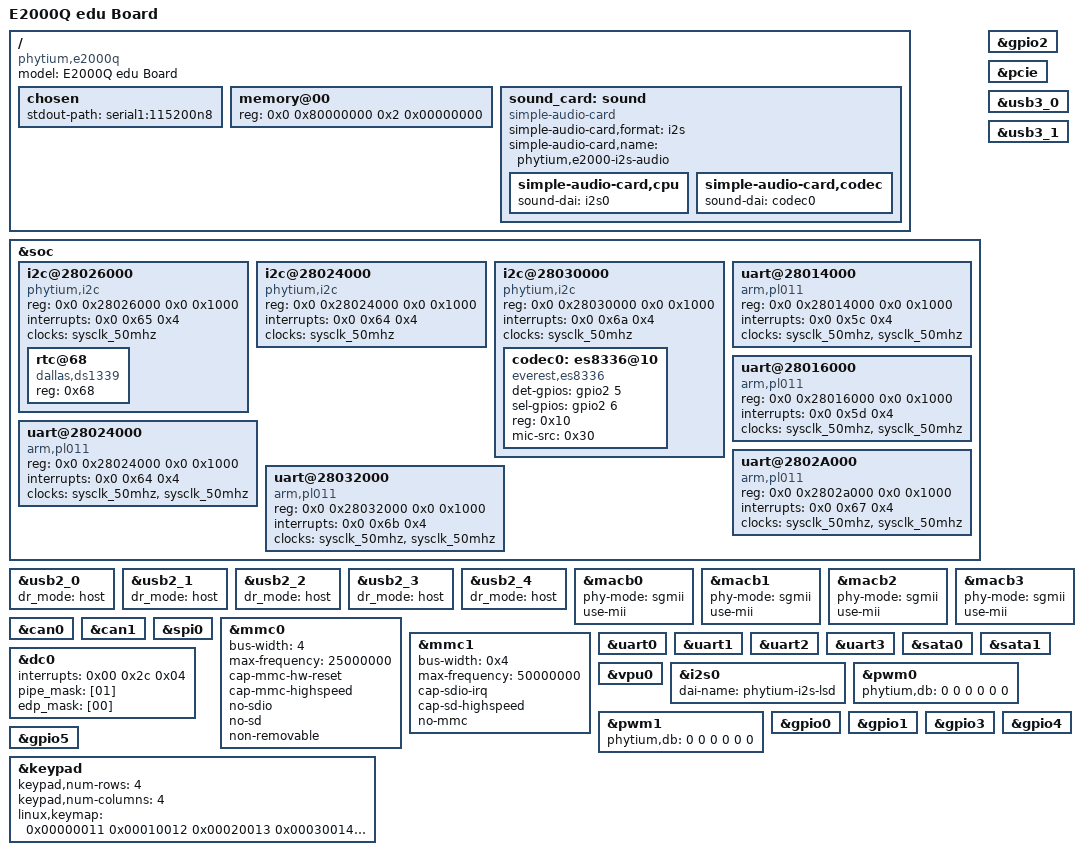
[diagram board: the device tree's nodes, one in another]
// SPDX-License-Identifier: GPL-2.0
/*
 * DTS file for Phytium E2000Q edu board
 *
 * Copyright (C) 2022, Phytium Technology Co., Ltd.
 *
 * Hongmin Qi <qihongmin@phytium.com.cn>
 */

/dts-v1/;
/memreserve/ 0x80000000 0x10000;

#include "e2000q.dtsi"

/{
	model = "E2000Q edu Board";
	compatible = "phytium,e2000q";

	chosen {
		stdout-path = "serial1:115200n8";
	};

	memory@00{
		device_type = "memory";
		reg = <0x0 0x80000000 0x2 0x00000000>;
	};

	sound_card: sound {
		compatible = "simple-audio-card";
		simple-audio-card,format = "i2s";
		simple-audio-card,name = "phytium,e2000-i2s-audio";
		simple-audio-card,cpu {
			sound-dai = <&i2s0>;
		};
		simple-audio-card,codec {
			sound-dai = <&codec0>;
		};
	};
};

&soc {
	i2c@28026000 {
		compatible = "phytium,i2c";
		reg = <0x0 0x28026000 0x0 0x1000>;
		interrupts = <0x0 0x65 0x4>;
		clocks = <&sysclk_50mhz>;
		#address-cells = <0x1>;
		#size-cells = <0x0>;
		status = "okay";

		rtc@68 {
			compatible = "dallas,ds1339";
			reg = <0x68>;
		};
	};

	i2c@28024000 {
		compatible = "phytium,i2c";
		reg = <0x0 0x28024000 0x0 0x1000>;
		interrupts = <0x0 0x64 0x4>;
		clocks = <&sysclk_50mhz>;
		#address-cells = <0x1>;
		#size-cells = <0x0>;
		status = "okay";
	};

	i2c@28030000 {
		compatible = "phytium,i2c";
		reg = <0x0 0x28030000 0x0 0x1000>;
		interrupts = <0x0 0x6a 0x4>;
		clocks = <&sysclk_50mhz>;
		#address-cells = <0x1>;
		#size-cells = <0x0>;
		status = "okay";

		codec0:es8336@10 {
			det-gpios = <&gpio2 5 0>;
			sel-gpios = <&gpio2 6 0>;
			#sound-dai-cells = <0x0>;
			compatible = "everest,es8336";
			reg = <0x10>;
			mic-src = <0x30>;
	   };
	};

	uart@28014000 {
		compatible = "arm,pl011", "arm,primecell";
		reg = <0x0 0x28014000 0x0 0x1000>;
		interrupts = <0x0 0x5c 0x4>;
		clocks = <&sysclk_50mhz &sysclk_50mhz>;
		clock-names = "uartclk", "apb_pclk";
		status = "okay";
	};

	uart@28016000 {
		compatible = "arm,pl011", "arm,primecell";
		reg = <0x0 0x28016000 0x0 0x1000>;
		interrupts = <0x0 0x5d 0x4>;
		clocks = <&sysclk_50mhz &sysclk_50mhz>;
		clock-names = "uartclk", "apb_pclk";
		status = "okay";
	};

	uart@28024000 {
		compatible = "arm,pl011", "arm,primecell";
		reg = <0x0 0x28024000 0x0 0x1000>;
		interrupts = <0x0 0x64 0x4>;
		clocks = <&sysclk_50mhz &sysclk_50mhz>;
		clock-names = "uartclk", "apb_pclk";
		status = "okay";
	};

	uart@2802A000 {
		compatible = "arm,pl011", "arm,primecell";
		reg = <0x0 0x2802a000 0x0 0x1000>;
		interrupts = <0x0 0x67 0x4>;
		clocks = <&sysclk_50mhz &sysclk_50mhz>;
		clock-names = "uartclk", "apb_pclk";
		status = "okay";
	};

	uart@28032000 {
		compatible = "arm,pl011", "arm,primecell";
		reg = <0x0 0x28032000 0x0 0x1000>;
		interrupts = <0x0 0x6b 0x4>;
		clocks = <&sysclk_50mhz &sysclk_50mhz>;
		clock-names = "uartclk", "apb_pclk";
		status = "okay";
	};
};

&gpio2 {
	status = "okay";
};

&pcie {
	status = "okay";
};

&usb3_0 {
	status = "okay";
};

&usb3_1 {
	//status = "okay";
};

&usb2_0 {
	dr_mode = "host";
	status = "okay";
};

&usb2_1 {
	dr_mode = "host";
	//status = "okay";
};

&usb2_2 {
	dr_mode = "host";
	//status = "okay";
};

&usb2_3 {
	dr_mode = "host";
	status = "okay";
};

&usb2_4 {
	dr_mode = "host";
	//status = "okay";
};

&macb0 {
	phy-mode = "sgmii";
	use-mii;
	//status = "okay";
};

&macb1 {
	phy-mode = "sgmii";
	use-mii;
	//status = "okay";
};

&macb2 {
	phy-mode = "sgmii";
	use-mii;
	//status = "okay";
};

&macb3 {
	phy-mode = "sgmii";
	use-mii;
	status = "okay";
};

&can0 {
	status = "okay";
};

&can1 {
	status = "okay";
};

&spi0 {
	status = "okay";
};

&mmc0 {
	bus-width = <4>;
	max-frequency = <25000000>;
	cap-mmc-hw-reset;
	cap-mmc-highspeed;
	no-sdio;
	no-sd;
	non-removable;
	status = "okay";
};

&mmc1 {
	bus-width = <0x4>;
	max-frequency = <50000000>;
	cap-sdio-irq;
	cap-sd-highspeed;
	no-mmc;
	status = "okay";
};

&uart0 {
	status = "okay";
};

&uart1 {
	status = "okay";
};

&uart2 {
	status = "okay";
};

&uart3 {
	status = "okay";
};

&sata0 {
	//status = "okay";
};

&sata1 {
	status = "okay";
};

&dc0 {
	interrupts = <0x00 0x2c 0x04>;
	status = "okay";
	pipe_mask = [01];
	edp_mask = [00];
};

&vpu0 {
	status = "okay";
};

&i2s0 {
	#sound-dai-cells = <0>;
	dai-name = "phytium-i2s-lsd";
	status = "okay";
};

&pwm0 {
	phytium,db = <0 0 0 0 0 0>;
	status = "okay";
};

&pwm1 {
	phytium,db = <0 0 0 0 0 0>;
	status = "okay";
};


&gpio0 {
	status = "okay";
};

&gpio1 {
	status = "okay";
};

&gpio2 {
	status = "okay";
};

&gpio3 {
	status = "okay";
};

&gpio4 {
	status = "okay";
};

&gpio5 {
	status = "okay";
};

&keypad {
	keypad,num-rows = <4>;
	keypad,num-columns = <4>;
	linux,keymap = <0x00000011
				    0x00010012
					0x00020013
					0x00030014
					0x01000021 /*KEY_21*/
					0x01010022 /*KEY_22*/
					0x01020023 /*KEY_23*/
					0x01030024 /*KEY_24*/
					0x02000031 /*KEY_31*/
					0x02010032 /*KEY_32*/
					0x02020033 /*KEY_33*/
					0x02030034 /*KEY_34*/
					0x03000041 /*KEY_41*/
					0x03010042 /*KEY_42*/
					0x03020043 /*KEY_43*/
					0x03030044 /*KEY_44*/>;
	status = "okay";
};
